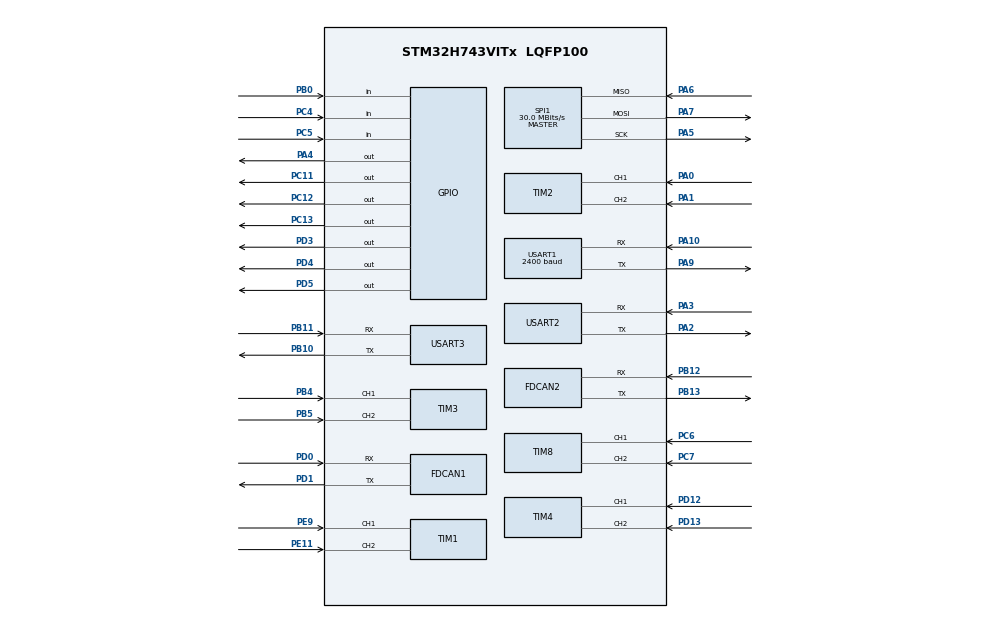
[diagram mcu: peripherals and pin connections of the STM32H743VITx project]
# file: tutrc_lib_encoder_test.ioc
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Dma.Request0=USART1_RX
Dma.Request1=USART2_RX
Dma.Request2=USART3_RX
Dma.USART1_RX.0.Direction=DMA_PERIPH_TO_MEMORY
Dma.USART1_RX.0.EventEnable=DISABLE
Dma.USART1_RX.0.FIFOMode=DMA_FIFOMODE_DISABLE
Dma.USART1_RX.0.Instance=DMA1_Stream0
Dma.USART1_RX.0.MemDataAlignment=DMA_MDATAALIGN_BYTE
Dma.USART1_RX.0.MemInc=DMA_MINC_ENABLE
Dma.USART1_RX.0.Mode=DMA_CIRCULAR
Dma.USART1_RX.0.PeriphDataAlignment=DMA_PDATAALIGN_BYTE
Dma.USART1_RX.0.PeriphInc=DMA_PINC_DISABLE
Dma.USART1_RX.0.Polarity=HAL_DMAMUX_REQ_GEN_RISING
Dma.USART1_RX.0.Priority=DMA_PRIORITY_LOW
Dma.USART1_RX.0.RequestNumber=1
Dma.USART1_RX.0.SignalID=NONE
Dma.USART1_RX.0.SyncEnable=DISABLE
Dma.USART1_RX.0.SyncPolarity=HAL_DMAMUX_SYNC_NO_EVENT
Dma.USART1_RX.0.SyncRequestNumber=1
Dma.USART1_RX.0.SyncSignalID=NONE
Dma.USART2_RX.1.Direction=DMA_PERIPH_TO_MEMORY
Dma.USART2_RX.1.EventEnable=DISABLE
Dma.USART2_RX.1.FIFOMode=DMA_FIFOMODE_DISABLE
Dma.USART2_RX.1.Instance=DMA1_Stream1
Dma.USART2_RX.1.MemDataAlignment=DMA_MDATAALIGN_BYTE
Dma.USART2_RX.1.MemInc=DMA_MINC_ENABLE
Dma.USART2_RX.1.Mode=DMA_CIRCULAR
Dma.USART2_RX.1.PeriphDataAlignment=DMA_PDATAALIGN_BYTE
Dma.USART2_RX.1.PeriphInc=DMA_PINC_DISABLE
Dma.USART2_RX.1.Polarity=HAL_DMAMUX_REQ_GEN_RISING
Dma.USART2_RX.1.Priority=DMA_PRIORITY_LOW
Dma.USART2_RX.1.RequestNumber=1
Dma.USART2_RX.1.SignalID=NONE
Dma.USART2_RX.1.SyncEnable=DISABLE
Dma.USART2_RX.1.SyncPolarity=HAL_DMAMUX_SYNC_NO_EVENT
Dma.USART2_RX.1.SyncRequestNumber=1
Dma.USART2_RX.1.SyncSignalID=NONE
Dma.USART3_RX.2.Direction=DMA_PERIPH_TO_MEMORY
Dma.USART3_RX.2.EventEnable=DISABLE
Dma.USART3_RX.2.FIFOMode=DMA_FIFOMODE_DISABLE
Dma.USART3_RX.2.Instance=DMA1_Stream2
Dma.USART3_RX.2.MemDataAlignment=DMA_MDATAALIGN_BYTE
Dma.USART3_RX.2.MemInc=DMA_MINC_ENABLE
Dma.USART3_RX.2.Mode=DMA_CIRCULAR
Dma.USART3_RX.2.PeriphDataAlignment=DMA_PDATAALIGN_BYTE
Dma.USART3_RX.2.PeriphInc=DMA_PINC_DISABLE
Dma.USART3_RX.2.Polarity=HAL_DMAMUX_REQ_GEN_RISING
Dma.USART3_RX.2.Priority=DMA_PRIORITY_LOW
Dma.USART3_RX.2.RequestNumber=1
Dma.USART3_RX.2.SignalID=NONE
Dma.USART3_RX.2.SyncEnable=DISABLE
Dma.USART3_RX.2.SyncPolarity=HAL_DMAMUX_SYNC_NO_EVENT
Dma.USART3_RX.2.SyncRequestNumber=1
Dma.USART3_RX.2.SyncSignalID=NONE
FDCAN1.NominalPrescaler=5
FDCAN1.NominalTimeSeg1=13
FDCAN1.RxBuffersNbr=64
FDCAN1.RxFifo0ElmtsNbr=64
FDCAN1.StdFiltersNbr=128
FDCAN1.TxFifoQueueElmtsNbr=32
FDCAN2.MessageRAMOffset=2560/2
FDCAN2.NominalPrescaler=5
FDCAN2.NominalTimeSeg1=13
FDCAN2.RxBuffersNbr=64
FDCAN2.RxFifo1ElmtsNbr=64
FDCAN2.StdFiltersNbr=128
FDCAN2.TxFifoQueueElmtsNbr=32
Mcu.Family=STM32H7
Mcu.Name=STM32H743VITx
Mcu.Package=LQFP100
NVIC.DMA1_Stream0_IRQn=true\:0\:0\:false\:false\:true\:false\:true\:true
NVIC.DMA1_Stream1_IRQn=true\:0\:0\:false\:false\:true\:false\:true\:true
NVIC.DMA1_Stream2_IRQn=true\:0\:0\:false\:false\:true\:false\:true\:true
NVIC.FDCAN1_IT0_IRQn=true\:0\:0\:true\:false\:true\:true\:true\:true
NVIC.FDCAN2_IT0_IRQn=true\:0\:0\:false\:false\:true\:true\:true\:true
NVIC.PriorityGroup=NVIC_PRIORITYGROUP_4
NVIC.TIM5_IRQn=true\:1\:0\:true\:false\:true\:true\:true\:true
NVIC.TIM6_DAC_IRQn=true\:0\:0\:false\:false\:true\:true\:true\:true
NVIC.TIM7_IRQn=true\:0\:0\:false\:false\:true\:true\:true\:true
NVIC.TIM8_UP_TIM13_IRQn=true\:1\:0\:true\:false\:true\:true\:true\:true
NVIC.USART3_IRQn=true\:0\:0\:false\:false\:true\:true\:true\:true
PA0.Signal=S_TIM2_CH1
PA1.Signal=S_TIM2_CH2
PA10.Mode=Asynchronous
PA10.Signal=USART1_RX
PA12.Signal=USART1_DE
PA13\ (JTMS/SWDIO).Mode=Serial_Wire
PA13\ (JTMS/SWDIO).Signal=DEBUG_JTMS-SWDIO
PA14\ (JTCK/SWCLK).Mode=Serial_Wire
PA14\ (JTCK/SWCLK).Signal=DEBUG_JTCK-SWCLK
PA2.Mode=Asynchronous
PA2.Signal=USART2_TX
PA3.Mode=Asynchronous
PA3.Signal=USART2_RX
PA4.Signal=GPIO_Output
PA5.Mode=Full_Duplex_Master
PA5.Signal=SPI1_SCK
PA6.Mode=Full_Duplex_Master
PA6.Signal=SPI1_MISO
PA7.Mode=Full_Duplex_Master
PA7.Signal=SPI1_MOSI
PA9.Mode=Asynchronous
PA9.Signal=USART1_TX
PB0.Signal=GPIO_Input
PB10.Mode=Asynchronous
PB10.Signal=USART3_TX
PB11.Mode=Asynchronous
PB11.Signal=USART3_RX
PB12.Mode=FDCAN_Activate
PB12.Signal=FDCAN2_RX
PB13.Mode=FDCAN_Activate
PB13.Signal=FDCAN2_TX
PB14.Signal=USART3_DE
PB3\ (JTDO/TRACESWO).Signal=DEBUG_JTDO-SWO
PB4\ (NJTRST).Signal=S_TIM3_CH1
PB5.Signal=S_TIM3_CH2
PB6.Signal=I2C1_SCL
PB9.Signal=I2C1_SDA
PC11.Signal=GPIO_Output
PC12.Signal=GPIO_Output
PC13.Signal=GPIO_Output
PC4.Signal=GPIO_Input
PC5.Signal=GPIO_Input
PC6.Signal=S_TIM8_CH1
PC7.Signal=S_TIM8_CH2
PD0.Mode=FDCAN_Activate
PD0.Signal=FDCAN1_RX
PD1.Mode=FDCAN_Activate
PD1.Signal=FDCAN1_TX
PD12.Signal=S_TIM4_CH1
PD13.Signal=S_TIM4_CH2
PD3.Signal=GPIO_Output
PD4.Signal=GPIO_Output
PD5.Signal=GPIO_Output
PE11.Signal=S_TIM1_CH2
PE9.Signal=S_TIM1_CH1
PH0-OSC_IN\ (PH0).Mode=HSE-External-Oscillator
PH0-OSC_IN\ (PH0).Signal=RCC_OSC_IN
PH1-OSC_OUT\ (PH1).Mode=HSE-External-Oscillator
PH1-OSC_OUT\ (PH1).Signal=RCC_OSC_OUT
ProjectManager.HeapSize=0x200
ProjectManager.StackSize=0x400
ProjectManager.TargetToolchain=STM32CubeIDE
RCC.ADCFreq_Value=60000000
RCC.APB1Freq_Value=120000000
RCC.APB2Freq_Value=120000000
RCC.APB3Freq_Value=120000000
RCC.APB4Freq_Value=120000000
RCC.CortexFreq_Value=480000000
RCC.D1PPRE=RCC_APB3_DIV2
RCC.D2PPRE1=RCC_APB1_DIV2
RCC.D2PPRE2=RCC_APB2_DIV2
RCC.D3PPRE=RCC_APB4_DIV2
RCC.DIVM1=2
RCC.DIVN1=60
RCC.DIVN2=240
RCC.DIVP2=4
RCC.DIVQ1=12
RCC.HCLKFreq_Value=240000000
RCC.HPRE=RCC_HCLK_DIV2
RCC.HSE_VALUE=32000000
RCC.PLLFRACN=0
RCC.PLLSourceVirtual=RCC_PLLSOURCE_HSE
RCC.PWR_Regulator_Voltage_Scale=PWR_REGULATOR_VOLTAGE_SCALE0
RCC.SPI123CLockSelection=RCC_SPI123CLKSOURCE_PLL2
RCC.SYSCLKFreq_VALUE=480000000
RCC.SYSCLKSource=RCC_SYSCLKSOURCE_PLLCLK
RCC.USBFreq_Value=80000000
SH.S_TIM1_CH1.0=TIM1_CH1,Encoder_Interface
SH.S_TIM1_CH2.0=TIM1_CH2,Encoder_Interface
SH.S_TIM2_CH1.0=TIM2_CH1,Encoder_Interface
SH.S_TIM2_CH2.0=TIM2_CH2,Encoder_Interface
SH.S_TIM3_CH1.0=TIM3_CH1,Encoder_Interface
SH.S_TIM3_CH2.0=TIM3_CH2,Encoder_Interface
SH.S_TIM4_CH1.0=TIM4_CH1,Encoder_Interface
SH.S_TIM4_CH2.0=TIM4_CH2,Encoder_Interface
SH.S_TIM8_CH1.0=TIM8_CH1,Encoder_Interface
SH.S_TIM8_CH2.0=TIM8_CH2,Encoder_Interface
SPI1.BaudRatePrescaler=SPI_BAUDRATEPRESCALER_2
SPI1.CalculateBaudRate=30.0 MBits/s
SPI1.DataSize=SPI_DATASIZE_8BIT
SPI1.Direction=SPI_DIRECTION_2LINES
SPI1.IOSwap=SPI_IO_SWAP_ENABLE
SPI1.MasterKeepIOState=SPI_MASTER_KEEP_IO_STATE_ENABLE
SPI1.MasterReceiverAutoSusp=SPI_MASTER_RX_AUTOSUSP_ENABLE
SPI1.Mode=SPI_MODE_MASTER
SPI1.NSSPMode=SPI_NSS_PULSE_ENABLE
SPI1.VirtualType=VM_MASTER
TIM1.EncoderMode=TIM_ENCODERMODE_TI12
TIM13.Period=10000-1
TIM13.Prescaler=240-1
TIM2.EncoderMode=TIM_ENCODERMODE_TI12
TIM3.EncoderMode=TIM_ENCODERMODE_TI12
TIM4.EncoderMode=TIM_ENCODERMODE_TI12
TIM5.Period=10000-1
TIM5.Prescaler=240-1
TIM6.Prescaler=240-1
TIM7.Period=1000-1
TIM7.Prescaler=240-1
TIM8.EncoderMode=TIM_ENCODERMODE_TI12
USART1.BaudRate=2400
USART1.VirtualMode-Asynchronous=VM_ASYNC
USART2.VirtualMode-Asynchronous=VM_ASYNC
USART3.VirtualMode-Asynchronous=VM_ASYNC
VP_TIM13_VS_ClockSourceINT.Mode=Enable_Timer
VP_TIM5_VS_ClockSourceINT.Mode=Internal
VP_TIM6_VS_ClockSourceINT.Mode=Enable_Timer
VP_TIM7_VS_ClockSourceINT.Mode=Enable_Timer
board=custom

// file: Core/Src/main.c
/* USER CODE BEGIN Header */
/**
  ******************************************************************************
  * @file           : main.c
  * @brief          : Main program body
  ******************************************************************************
  * @attention
  *
  * <h2><center>&copy; Copyright (c) 2024 STMicroelectronics.
  * All rights reserved.</center></h2>
  *
  * This software component is licensed by ST under BSD 3-Clause license,
  * the "License"; You may not use this file except in compliance with the
  * License. You may obtain a copy of the License at:
  *                        opensource.org/licenses/BSD-3-Clause
  *
  ******************************************************************************
  */
/* USER CODE END Header */
#include "main.h"

FDCAN_HandleTypeDef hfdcan1;
FDCAN_HandleTypeDef hfdcan2;

SPI_HandleTypeDef hspi1;

TIM_HandleTypeDef htim1;
TIM_HandleTypeDef htim2;
TIM_HandleTypeDef htim3;
TIM_HandleTypeDef htim4;
TIM_HandleTypeDef htim5;
TIM_HandleTypeDef htim6;
TIM_HandleTypeDef htim7;
TIM_HandleTypeDef htim8;
TIM_HandleTypeDef htim13;

UART_HandleTypeDef huart1;
UART_HandleTypeDef huart2;
UART_HandleTypeDef huart3;
DMA_HandleTypeDef hdma_usart1_rx;
DMA_HandleTypeDef hdma_usart2_rx;
DMA_HandleTypeDef hdma_usart3_rx;

void SystemClock_Config(void);
static void MX_GPIO_Init(void);
static void MX_DMA_Init(void);
static void MX_FDCAN2_Init(void);
static void MX_TIM1_Init(void);
static void MX_TIM2_Init(void);
static void MX_TIM3_Init(void);
static void MX_TIM4_Init(void);
static void MX_TIM8_Init(void);
static void MX_USART2_UART_Init(void);
static void MX_TIM6_Init(void);
static void MX_TIM7_Init(void);
static void MX_SPI1_Init(void);
static void MX_TIM13_Init(void);
static void MX_USART1_UART_Init(void);
static void MX_FDCAN1_Init(void);
static void MX_USART3_UART_Init(void);
static void MX_TIM5_Init(void);
/* USER CODE BEGIN PFP */
void cppmain();
/* USER CODE END PFP */

int main(void)
{

  /* MCU Configuration--------------------------------------------------------*/

  /* Reset of all peripherals, Initializes the Flash interface and the Systick. */
  HAL_Init();

  /* Configure the system clock */
  SystemClock_Config();

  /* Initialize all configured peripherals */
  MX_GPIO_Init();
  MX_DMA_Init();
  MX_FDCAN2_Init();
  MX_TIM1_Init();
  MX_TIM2_Init();
  MX_TIM3_Init();
  MX_TIM4_Init();
  MX_TIM8_Init();
  MX_USART2_UART_Init();
  MX_TIM6_Init();
  MX_TIM7_Init();
  MX_SPI1_Init();
  MX_TIM13_Init();
  MX_USART1_UART_Init();
  MX_FDCAN1_Init();
  MX_USART3_UART_Init();
  MX_TIM5_Init();
  /* USER CODE BEGIN 2 */
cppmain();
  /* USER CODE END 2 */

  /* Infinite loop */
  while (1)
  {

  }
}

void SystemClock_Config(void)
{
  RCC_OscInitTypeDef RCC_OscInitStruct = {0};
  RCC_ClkInitTypeDef RCC_ClkInitStruct = {0};

  /** Supply configuration update enable
  */
  HAL_PWREx_ConfigSupply(PWR_LDO_SUPPLY);
  /** Configure the main internal regulator output voltage
  */
  __HAL_PWR_VOLTAGESCALING_CONFIG(PWR_REGULATOR_VOLTAGE_SCALE0);

  while(!__HAL_PWR_GET_FLAG(PWR_FLAG_VOSRDY)) {}
  /** Macro to configure the PLL clock source
  */
  __HAL_RCC_PLL_PLLSOURCE_CONFIG(RCC_PLLSOURCE_HSE);
  /** Initializes the RCC Oscillators according to the specified parameters
  * in the RCC_OscInitTypeDef structure.
  */
  RCC_OscInitStruct.OscillatorType = RCC_OSCILLATORTYPE_HSE;
  RCC_OscInitStruct.HSEState = RCC_HSE_ON;
  RCC_OscInitStruct.PLL.PLLState = RCC_PLL_ON;
  RCC_OscInitStruct.PLL.PLLSource = RCC_PLLSOURCE_HSE;
  RCC_OscInitStruct.PLL.PLLM = 2;
  RCC_OscInitStruct.PLL.PLLN = 60;
  RCC_OscInitStruct.PLL.PLLP = 2;
  RCC_OscInitStruct.PLL.PLLQ = 12;
  RCC_OscInitStruct.PLL.PLLR = 2;
  RCC_OscInitStruct.PLL.PLLRGE = RCC_PLL1VCIRANGE_3;
  RCC_OscInitStruct.PLL.PLLVCOSEL = RCC_PLL1VCOWIDE;
  RCC_OscInitStruct.PLL.PLLFRACN = 0;
  if (HAL_RCC_OscConfig(&RCC_OscInitStruct) != HAL_OK)
  {
    Error_Handler();
  }
  /** Initializes the CPU, AHB and APB buses clocks
  */
  RCC_ClkInitStruct.ClockType = RCC_CLOCKTYPE_HCLK|RCC_CLOCKTYPE_SYSCLK
                              |RCC_CLOCKTYPE_PCLK1|RCC_CLOCKTYPE_PCLK2
                              |RCC_CLOCKTYPE_D3PCLK1|RCC_CLOCKTYPE_D1PCLK1;
  RCC_ClkInitStruct.SYSCLKSource = RCC_SYSCLKSOURCE_PLLCLK;
  RCC_ClkInitStruct.SYSCLKDivider = RCC_SYSCLK_DIV1;
  RCC_ClkInitStruct.AHBCLKDivider = RCC_HCLK_DIV2;
  RCC_ClkInitStruct.APB3CLKDivider = RCC_APB3_DIV2;
  RCC_ClkInitStruct.APB1CLKDivider = RCC_APB1_DIV2;
  RCC_ClkInitStruct.APB2CLKDivider = RCC_APB2_DIV2;
  RCC_ClkInitStruct.APB4CLKDivider = RCC_APB4_DIV2;

  if (HAL_RCC_ClockConfig(&RCC_ClkInitStruct, FLASH_LATENCY_4) != HAL_OK)
  {
    Error_Handler();
  }
}

static void MX_FDCAN1_Init(void)
{

  hfdcan1.Instance = FDCAN1;
  hfdcan1.Init.FrameFormat = FDCAN_FRAME_CLASSIC;
  hfdcan1.Init.Mode = FDCAN_MODE_NORMAL;
  hfdcan1.Init.AutoRetransmission = DISABLE;
  hfdcan1.Init.TransmitPause = DISABLE;
  hfdcan1.Init.ProtocolException = DISABLE;
  hfdcan1.Init.NominalPrescaler = 5;
  hfdcan1.Init.NominalSyncJumpWidth = 1;
  hfdcan1.Init.NominalTimeSeg1 = 13;
  hfdcan1.Init.NominalTimeSeg2 = 2;
  hfdcan1.Init.DataPrescaler = 1;
  hfdcan1.Init.DataSyncJumpWidth = 1;
  hfdcan1.Init.DataTimeSeg1 = 1;
  hfdcan1.Init.DataTimeSeg2 = 1;
  hfdcan1.Init.MessageRAMOffset = 0;
  hfdcan1.Init.StdFiltersNbr = 128;
  hfdcan1.Init.ExtFiltersNbr = 0;
  hfdcan1.Init.RxFifo0ElmtsNbr = 64;
  hfdcan1.Init.RxFifo0ElmtSize = FDCAN_DATA_BYTES_8;
  hfdcan1.Init.RxFifo1ElmtsNbr = 0;
  hfdcan1.Init.RxFifo1ElmtSize = FDCAN_DATA_BYTES_8;
  hfdcan1.Init.RxBuffersNbr = 64;
  hfdcan1.Init.RxBufferSize = FDCAN_DATA_BYTES_8;
  hfdcan1.Init.TxEventsNbr = 0;
  hfdcan1.Init.TxBuffersNbr = 0;
  hfdcan1.Init.TxFifoQueueElmtsNbr = 32;
  hfdcan1.Init.TxFifoQueueMode = FDCAN_TX_FIFO_OPERATION;
  hfdcan1.Init.TxElmtSize = FDCAN_DATA_BYTES_8;
  if (HAL_FDCAN_Init(&hfdcan1) != HAL_OK)
  {
    Error_Handler();
  }

}

static void MX_FDCAN2_Init(void)
{

  hfdcan2.Instance = FDCAN2;
  hfdcan2.Init.FrameFormat = FDCAN_FRAME_CLASSIC;
  hfdcan2.Init.Mode = FDCAN_MODE_NORMAL;
  hfdcan2.Init.AutoRetransmission = DISABLE;
  hfdcan2.Init.TransmitPause = DISABLE;
  hfdcan2.Init.ProtocolException = DISABLE;
  hfdcan2.Init.NominalPrescaler = 5;
  hfdcan2.Init.NominalSyncJumpWidth = 1;
  hfdcan2.Init.NominalTimeSeg1 = 13;
  hfdcan2.Init.NominalTimeSeg2 = 2;
  hfdcan2.Init.DataPrescaler = 1;
  hfdcan2.Init.DataSyncJumpWidth = 1;
  hfdcan2.Init.DataTimeSeg1 = 1;
  hfdcan2.Init.DataTimeSeg2 = 1;
  hfdcan2.Init.MessageRAMOffset = 2560/2;
  hfdcan2.Init.StdFiltersNbr = 128;
  hfdcan2.Init.ExtFiltersNbr = 0;
  hfdcan2.Init.RxFifo0ElmtsNbr = 0;
  hfdcan2.Init.RxFifo0ElmtSize = FDCAN_DATA_BYTES_8;
  hfdcan2.Init.RxFifo1ElmtsNbr = 64;
  hfdcan2.Init.RxFifo1ElmtSize = FDCAN_DATA_BYTES_8;
  hfdcan2.Init.RxBuffersNbr = 64;
  hfdcan2.Init.RxBufferSize = FDCAN_DATA_BYTES_8;
  hfdcan2.Init.TxEventsNbr = 0;
  hfdcan2.Init.TxBuffersNbr = 0;
  hfdcan2.Init.TxFifoQueueElmtsNbr = 32;
  hfdcan2.Init.TxFifoQueueMode = FDCAN_TX_FIFO_OPERATION;
  hfdcan2.Init.TxElmtSize = FDCAN_DATA_BYTES_8;
  if (HAL_FDCAN_Init(&hfdcan2) != HAL_OK)
  {
    Error_Handler();
  }

}

static void MX_SPI1_Init(void)
{

  /* SPI1 parameter configuration*/
  hspi1.Instance = SPI1;
  hspi1.Init.Mode = SPI_MODE_MASTER;
  hspi1.Init.Direction = SPI_DIRECTION_2LINES;
  hspi1.Init.DataSize = SPI_DATASIZE_8BIT;
  hspi1.Init.CLKPolarity = SPI_POLARITY_LOW;
  hspi1.Init.CLKPhase = SPI_PHASE_1EDGE;
  hspi1.Init.NSS = SPI_NSS_SOFT;
  hspi1.Init.BaudRatePrescaler = SPI_BAUDRATEPRESCALER_2;
  hspi1.Init.FirstBit = SPI_FIRSTBIT_MSB;
  hspi1.Init.TIMode = SPI_TIMODE_DISABLE;
  hspi1.Init.CRCCalculation = SPI_CRCCALCULATION_DISABLE;
  hspi1.Init.CRCPolynomial = 0x0;
  hspi1.Init.NSSPMode = SPI_NSS_PULSE_ENABLE;
  hspi1.Init.NSSPolarity = SPI_NSS_POLARITY_LOW;
  hspi1.Init.FifoThreshold = SPI_FIFO_THRESHOLD_01DATA;
  hspi1.Init.TxCRCInitializationPattern = SPI_CRC_INITIALIZATION_ALL_ZERO_PATTERN;
  hspi1.Init.RxCRCInitializationPattern = SPI_CRC_INITIALIZATION_ALL_ZERO_PATTERN;
  hspi1.Init.MasterSSIdleness = SPI_MASTER_SS_IDLENESS_00CYCLE;
  hspi1.Init.MasterInterDataIdleness = SPI_MASTER_INTERDATA_IDLENESS_00CYCLE;
  hspi1.Init.MasterReceiverAutoSusp = SPI_MASTER_RX_AUTOSUSP_ENABLE;
  hspi1.Init.MasterKeepIOState = SPI_MASTER_KEEP_IO_STATE_ENABLE;
  hspi1.Init.IOSwap = SPI_IO_SWAP_ENABLE;
  if (HAL_SPI_Init(&hspi1) != HAL_OK)
  {
    Error_Handler();
  }

}

static void MX_TIM1_Init(void)
{

  TIM_Encoder_InitTypeDef sConfig = {0};
  TIM_MasterConfigTypeDef sMasterConfig = {0};

  htim1.Instance = TIM1;
  htim1.Init.Prescaler = 0;
  htim1.Init.CounterMode = TIM_COUNTERMODE_UP;
  htim1.Init.Period = 65535;
  htim1.Init.ClockDivision = TIM_CLOCKDIVISION_DIV1;
  htim1.Init.RepetitionCounter = 0;
  htim1.Init.AutoReloadPreload = TIM_AUTORELOAD_PRELOAD_DISABLE;
  sConfig.EncoderMode = TIM_ENCODERMODE_TI12;
  sConfig.IC1Polarity = TIM_ICPOLARITY_RISING;
  sConfig.IC1Selection = TIM_ICSELECTION_DIRECTTI;
  sConfig.IC1Prescaler = TIM_ICPSC_DIV1;
  sConfig.IC1Filter = 0;
  sConfig.IC2Polarity = TIM_ICPOLARITY_RISING;
  sConfig.IC2Selection = TIM_ICSELECTION_DIRECTTI;
  sConfig.IC2Prescaler = TIM_ICPSC_DIV1;
  sConfig.IC2Filter = 0;
  if (HAL_TIM_Encoder_Init(&htim1, &sConfig) != HAL_OK)
  {
    Error_Handler();
  }
  sMasterConfig.MasterOutputTrigger = TIM_TRGO_RESET;
  sMasterConfig.MasterOutputTrigger2 = TIM_TRGO2_RESET;
  sMasterConfig.MasterSlaveMode = TIM_MASTERSLAVEMODE_DISABLE;
  if (HAL_TIMEx_MasterConfigSynchronization(&htim1, &sMasterConfig) != HAL_OK)
  {
    Error_Handler();
  }

}

static void MX_TIM2_Init(void)
{

  TIM_Encoder_InitTypeDef sConfig = {0};
  TIM_MasterConfigTypeDef sMasterConfig = {0};

  htim2.Instance = TIM2;
  htim2.Init.Prescaler = 0;
  htim2.Init.CounterMode = TIM_COUNTERMODE_UP;
  htim2.Init.Period = 4294967295;
  htim2.Init.ClockDivision = TIM_CLOCKDIVISION_DIV1;
  htim2.Init.AutoReloadPreload = TIM_AUTORELOAD_PRELOAD_DISABLE;
  sConfig.EncoderMode = TIM_ENCODERMODE_TI12;
  sConfig.IC1Polarity = TIM_ICPOLARITY_RISING;
  sConfig.IC1Selection = TIM_ICSELECTION_DIRECTTI;
  sConfig.IC1Prescaler = TIM_ICPSC_DIV1;
  sConfig.IC1Filter = 0;
  sConfig.IC2Polarity = TIM_ICPOLARITY_RISING;
  sConfig.IC2Selection = TIM_ICSELECTION_DIRECTTI;
  sConfig.IC2Prescaler = TIM_ICPSC_DIV1;
  sConfig.IC2Filter = 0;
  if (HAL_TIM_Encoder_Init(&htim2, &sConfig) != HAL_OK)
  {
    Error_Handler();
  }
  sMasterConfig.MasterOutputTrigger = TIM_TRGO_RESET;
  sMasterConfig.MasterSlaveMode = TIM_MASTERSLAVEMODE_DISABLE;
  if (HAL_TIMEx_MasterConfigSynchronization(&htim2, &sMasterConfig) != HAL_OK)
  {
    Error_Handler();
  }

}

static void MX_TIM3_Init(void)
{

  TIM_Encoder_InitTypeDef sConfig = {0};
  TIM_MasterConfigTypeDef sMasterConfig = {0};

  htim3.Instance = TIM3;
  htim3.Init.Prescaler = 0;
  htim3.Init.CounterMode = TIM_COUNTERMODE_UP;
  htim3.Init.Period = 65535;
  htim3.Init.ClockDivision = TIM_CLOCKDIVISION_DIV1;
  htim3.Init.AutoReloadPreload = TIM_AUTORELOAD_PRELOAD_DISABLE;
  sConfig.EncoderMode = TIM_ENCODERMODE_TI12;
  sConfig.IC1Polarity = TIM_ICPOLARITY_RISING;
  sConfig.IC1Selection = TIM_ICSELECTION_DIRECTTI;
  sConfig.IC1Prescaler = TIM_ICPSC_DIV1;
  sConfig.IC1Filter = 0;
  sConfig.IC2Polarity = TIM_ICPOLARITY_RISING;
  sConfig.IC2Selection = TIM_ICSELECTION_DIRECTTI;
  sConfig.IC2Prescaler = TIM_ICPSC_DIV1;
  sConfig.IC2Filter = 0;
  if (HAL_TIM_Encoder_Init(&htim3, &sConfig) != HAL_OK)
  {
    Error_Handler();
  }
  sMasterConfig.MasterOutputTrigger = TIM_TRGO_RESET;
  sMasterConfig.MasterSlaveMode = TIM_MASTERSLAVEMODE_DISABLE;
  if (HAL_TIMEx_MasterConfigSynchronization(&htim3, &sMasterConfig) != HAL_OK)
  {
    Error_Handler();
  }

}

static void MX_TIM4_Init(void)
{

  TIM_Encoder_InitTypeDef sConfig = {0};
  TIM_MasterConfigTypeDef sMasterConfig = {0};

  htim4.Instance = TIM4;
  htim4.Init.Prescaler = 0;
  htim4.Init.CounterMode = TIM_COUNTERMODE_UP;
  htim4.Init.Period = 65535;
  htim4.Init.ClockDivision = TIM_CLOCKDIVISION_DIV1;
  htim4.Init.AutoReloadPreload = TIM_AUTORELOAD_PRELOAD_DISABLE;
  sConfig.EncoderMode = TIM_ENCODERMODE_TI12;
  sConfig.IC1Polarity = TIM_ICPOLARITY_RISING;
  sConfig.IC1Selection = TIM_ICSELECTION_DIRECTTI;
  sConfig.IC1Prescaler = TIM_ICPSC_DIV1;
  sConfig.IC1Filter = 0;
  sConfig.IC2Polarity = TIM_ICPOLARITY_RISING;
  sConfig.IC2Selection = TIM_ICSELECTION_DIRECTTI;
  sConfig.IC2Prescaler = TIM_ICPSC_DIV1;
  sConfig.IC2Filter = 0;
  if (HAL_TIM_Encoder_Init(&htim4, &sConfig) != HAL_OK)
  {
    Error_Handler();
  }
  sMasterConfig.MasterOutputTrigger = TIM_TRGO_RESET;
  sMasterConfig.MasterSlaveMode = TIM_MASTERSLAVEMODE_DISABLE;
  if (HAL_TIMEx_MasterConfigSynchronization(&htim4, &sMasterConfig) != HAL_OK)
  {
    Error_Handler();
  }

}

static void MX_TIM5_Init(void)
{

  TIM_ClockConfigTypeDef sClockSourceConfig = {0};
  TIM_MasterConfigTypeDef sMasterConfig = {0};

  htim5.Instance = TIM5;
  htim5.Init.Prescaler = 240-1;
  htim5.Init.CounterMode = TIM_COUNTERMODE_UP;
  htim5.Init.Period = 10000-1;
  htim5.Init.ClockDivision = TIM_CLOCKDIVISION_DIV1;
  htim5.Init.AutoReloadPreload = TIM_AUTORELOAD_PRELOAD_DISABLE;
  if (HAL_TIM_Base_Init(&htim5) != HAL_OK)
  {
    Error_Handler();
  }
  sClockSourceConfig.ClockSource = TIM_CLOCKSOURCE_INTERNAL;
  if (HAL_TIM_ConfigClockSource(&htim5, &sClockSourceConfig) != HAL_OK)
  {
    Error_Handler();
  }
  sMasterConfig.MasterOutputTrigger = TIM_TRGO_RESET;
  sMasterConfig.MasterSlaveMode = TIM_MASTERSLAVEMODE_DISABLE;
  if (HAL_TIMEx_MasterConfigSynchronization(&htim5, &sMasterConfig) != HAL_OK)
  {
    Error_Handler();
  }

}

static void MX_TIM6_Init(void)
{

  TIM_MasterConfigTypeDef sMasterConfig = {0};

  htim6.Instance = TIM6;
  htim6.Init.Prescaler = 240-1;
  htim6.Init.CounterMode = TIM_COUNTERMODE_UP;
  htim6.Init.Period = 65535;
  htim6.Init.AutoReloadPreload = TIM_AUTORELOAD_PRELOAD_DISABLE;
  if (HAL_TIM_Base_Init(&htim6) != HAL_OK)
  {
    Error_Handler();
  }
  sMasterConfig.MasterOutputTrigger = TIM_TRGO_RESET;
  sMasterConfig.MasterSlaveMode = TIM_MASTERSLAVEMODE_DISABLE;
  if (HAL_TIMEx_MasterConfigSynchronization(&htim6, &sMasterConfig) != HAL_OK)
  {
    Error_Handler();
  }

}

static void MX_TIM7_Init(void)
{

  TIM_MasterConfigTypeDef sMasterConfig = {0};

  htim7.Instance = TIM7;
  htim7.Init.Prescaler = 240-1;
  htim7.Init.CounterMode = TIM_COUNTERMODE_UP;
  htim7.Init.Period = 1000-1;
  htim7.Init.AutoReloadPreload = TIM_AUTORELOAD_PRELOAD_DISABLE;
  if (HAL_TIM_Base_Init(&htim7) != HAL_OK)
  {
    Error_Handler();
  }
  sMasterConfig.MasterOutputTrigger = TIM_TRGO_RESET;
  sMasterConfig.MasterSlaveMode = TIM_MASTERSLAVEMODE_DISABLE;
  if (HAL_TIMEx_MasterConfigSynchronization(&htim7, &sMasterConfig) != HAL_OK)
  {
    Error_Handler();
  }

}

static void MX_TIM8_Init(void)
{

  TIM_Encoder_InitTypeDef sConfig = {0};
  TIM_MasterConfigTypeDef sMasterConfig = {0};

  htim8.Instance = TIM8;
  htim8.Init.Prescaler = 0;
  htim8.Init.CounterMode = TIM_COUNTERMODE_UP;
  htim8.Init.Period = 65535;
  htim8.Init.ClockDivision = TIM_CLOCKDIVISION_DIV1;
  htim8.Init.RepetitionCounter = 0;
  htim8.Init.AutoReloadPreload = TIM_AUTORELOAD_PRELOAD_DISABLE;
  sConfig.EncoderMode = TIM_ENCODERMODE_TI12;
  sConfig.IC1Polarity = TIM_ICPOLARITY_RISING;
  sConfig.IC1Selection = TIM_ICSELECTION_DIRECTTI;
  sConfig.IC1Prescaler = TIM_ICPSC_DIV1;
  sConfig.IC1Filter = 0;
  sConfig.IC2Polarity = TIM_ICPOLARITY_RISING;
  sConfig.IC2Selection = TIM_ICSELECTION_DIRECTTI;
  sConfig.IC2Prescaler = TIM_ICPSC_DIV1;
  sConfig.IC2Filter = 0;
  if (HAL_TIM_Encoder_Init(&htim8, &sConfig) != HAL_OK)
  {
    Error_Handler();
  }
  sMasterConfig.MasterOutputTrigger = TIM_TRGO_RESET;
  sMasterConfig.MasterOutputTrigger2 = TIM_TRGO2_RESET;
  sMasterConfig.MasterSlaveMode = TIM_MASTERSLAVEMODE_DISABLE;
  if (HAL_TIMEx_MasterConfigSynchronization(&htim8, &sMasterConfig) != HAL_OK)
  {
    Error_Handler();
  }

}

static void MX_TIM13_Init(void)
{

  htim13.Instance = TIM13;
  htim13.Init.Prescaler = 240-1;
  htim13.Init.CounterMode = TIM_COUNTERMODE_UP;
  htim13.Init.Period = 10000-1;
  htim13.Init.ClockDivision = TIM_CLOCKDIVISION_DIV1;
  htim13.Init.AutoReloadPreload = TIM_AUTORELOAD_PRELOAD_DISABLE;
  if (HAL_TIM_Base_Init(&htim13) != HAL_OK)
  {
    Error_Handler();
  }

}

static void MX_USART1_UART_Init(void)
{

  huart1.Instance = USART1;
  huart1.Init.BaudRate = 2400;
  huart1.Init.WordLength = UART_WORDLENGTH_8B;
  huart1.Init.StopBits = UART_STOPBITS_1;
  huart1.Init.Parity = UART_PARITY_NONE;
  huart1.Init.Mode = UART_MODE_TX_RX;
  huart1.Init.HwFlowCtl = UART_HWCONTROL_NONE;
  huart1.Init.OverSampling = UART_OVERSAMPLING_16;
  huart1.Init.OneBitSampling = UART_ONE_BIT_SAMPLE_DISABLE;
  huart1.Init.ClockPrescaler = UART_PRESCALER_DIV1;
  huart1.AdvancedInit.AdvFeatureInit = UART_ADVFEATURE_NO_INIT;
  if (HAL_UART_Init(&huart1) != HAL_OK)
  {
    Error_Handler();
  }
  if (HAL_UARTEx_SetTxFifoThreshold(&huart1, UART_TXFIFO_THRESHOLD_1_8) != HAL_OK)
  {
    Error_Handler();
  }
  if (HAL_UARTEx_SetRxFifoThreshold(&huart1, UART_RXFIFO_THRESHOLD_1_8) != HAL_OK)
  {
    Error_Handler();
  }
  if (HAL_UARTEx_DisableFifoMode(&huart1) != HAL_OK)
  {
    Error_Handler();
  }

}

static void MX_USART2_UART_Init(void)
{

  huart2.Instance = USART2;
  huart2.Init.BaudRate = 115200;
  huart2.Init.WordLength = UART_WORDLENGTH_8B;
  huart2.Init.StopBits = UART_STOPBITS_1;
  huart2.Init.Parity = UART_PARITY_NONE;
  huart2.Init.Mode = UART_MODE_TX_RX;
  huart2.Init.HwFlowCtl = UART_HWCONTROL_NONE;
  huart2.Init.OverSampling = UART_OVERSAMPLING_16;
  huart2.Init.OneBitSampling = UART_ONE_BIT_SAMPLE_DISABLE;
  huart2.Init.ClockPrescaler = UART_PRESCALER_DIV1;
  huart2.AdvancedInit.AdvFeatureInit = UART_ADVFEATURE_NO_INIT;
  if (HAL_UART_Init(&huart2) != HAL_OK)
  {
    Error_Handler();
  }
  if (HAL_UARTEx_SetTxFifoThreshold(&huart2, UART_TXFIFO_THRESHOLD_1_8) != HAL_OK)
  {
    Error_Handler();
  }
  if (HAL_UARTEx_SetRxFifoThreshold(&huart2, UART_RXFIFO_THRESHOLD_1_8) != HAL_OK)
  {
    Error_Handler();
  }
  if (HAL_UARTEx_DisableFifoMode(&huart2) != HAL_OK)
  {
    Error_Handler();
  }

}

static void MX_USART3_UART_Init(void)
{

  huart3.Instance = USART3;
  huart3.Init.BaudRate = 115200;
  huart3.Init.WordLength = UART_WORDLENGTH_8B;
  huart3.Init.StopBits = UART_STOPBITS_1;
  huart3.Init.Parity = UART_PARITY_NONE;
  huart3.Init.Mode = UART_MODE_TX_RX;
  huart3.Init.HwFlowCtl = UART_HWCONTROL_NONE;
  huart3.Init.OverSampling = UART_OVERSAMPLING_16;
  huart3.Init.OneBitSampling = UART_ONE_BIT_SAMPLE_DISABLE;
  huart3.Init.ClockPrescaler = UART_PRESCALER_DIV1;
  huart3.AdvancedInit.AdvFeatureInit = UART_ADVFEATURE_NO_INIT;
  if (HAL_UART_Init(&huart3) != HAL_OK)
  {
    Error_Handler();
  }
  if (HAL_UARTEx_SetTxFifoThreshold(&huart3, UART_TXFIFO_THRESHOLD_1_8) != HAL_OK)
  {
    Error_Handler();
  }
  if (HAL_UARTEx_SetRxFifoThreshold(&huart3, UART_RXFIFO_THRESHOLD_1_8) != HAL_OK)
  {
    Error_Handler();
  }
  if (HAL_UARTEx_DisableFifoMode(&huart3) != HAL_OK)
  {
    Error_Handler();
  }

}

static void MX_DMA_Init(void)
{

  /* DMA controller clock enable */
  __HAL_RCC_DMA1_CLK_ENABLE();

  /* DMA interrupt init */
  /* DMA1_Stream0_IRQn interrupt configuration */
  HAL_NVIC_SetPriority(DMA1_Stream0_IRQn, 0, 0);
  HAL_NVIC_EnableIRQ(DMA1_Stream0_IRQn);
  /* DMA1_Stream1_IRQn interrupt configuration */
  HAL_NVIC_SetPriority(DMA1_Stream1_IRQn, 0, 0);
  HAL_NVIC_EnableIRQ(DMA1_Stream1_IRQn);
  /* DMA1_Stream2_IRQn interrupt configuration */
  HAL_NVIC_SetPriority(DMA1_Stream2_IRQn, 0, 0);
  HAL_NVIC_EnableIRQ(DMA1_Stream2_IRQn);

}

static void MX_GPIO_Init(void)
{
  GPIO_InitTypeDef GPIO_InitStruct = {0};

  /* GPIO Ports Clock Enable */
  __HAL_RCC_GPIOC_CLK_ENABLE();
  __HAL_RCC_GPIOH_CLK_ENABLE();
  __HAL_RCC_GPIOA_CLK_ENABLE();
  __HAL_RCC_GPIOB_CLK_ENABLE();
  __HAL_RCC_GPIOE_CLK_ENABLE();
  __HAL_RCC_GPIOD_CLK_ENABLE();

  /*Configure GPIO pin Output Level */
  HAL_GPIO_WritePin(GPIOC, GPIO_PIN_13|GPIO_PIN_11|GPIO_PIN_12, GPIO_PIN_RESET);

  /*Configure GPIO pin Output Level */
  HAL_GPIO_WritePin(GPIOA, GPIO_PIN_4, GPIO_PIN_RESET);

  /*Configure GPIO pin Output Level */
  HAL_GPIO_WritePin(GPIOD, GPIO_PIN_3|GPIO_PIN_4|GPIO_PIN_5, GPIO_PIN_RESET);

  /*Configure GPIO pins : PC13 PC11 PC12 */
  GPIO_InitStruct.Pin = GPIO_PIN_13|GPIO_PIN_11|GPIO_PIN_12;
  GPIO_InitStruct.Mode = GPIO_MODE_OUTPUT_PP;
  GPIO_InitStruct.Pull = GPIO_NOPULL;
  GPIO_InitStruct.Speed = GPIO_SPEED_FREQ_LOW;
  HAL_GPIO_Init(GPIOC, &GPIO_InitStruct);

  /*Configure GPIO pin : PA4 */
  GPIO_InitStruct.Pin = GPIO_PIN_4;
  GPIO_InitStruct.Mode = GPIO_MODE_OUTPUT_PP;
  GPIO_InitStruct.Pull = GPIO_NOPULL;
  GPIO_InitStruct.Speed = GPIO_SPEED_FREQ_LOW;
  HAL_GPIO_Init(GPIOA, &GPIO_InitStruct);

  /*Configure GPIO pins : PC4 PC5 */
  GPIO_InitStruct.Pin = GPIO_PIN_4|GPIO_PIN_5;
  GPIO_InitStruct.Mode = GPIO_MODE_INPUT;
  GPIO_InitStruct.Pull = GPIO_NOPULL;
  HAL_GPIO_Init(GPIOC, &GPIO_InitStruct);

  /*Configure GPIO pin : PB0 */
  GPIO_InitStruct.Pin = GPIO_PIN_0;
  GPIO_InitStruct.Mode = GPIO_MODE_INPUT;
  GPIO_InitStruct.Pull = GPIO_NOPULL;
  HAL_GPIO_Init(GPIOB, &GPIO_InitStruct);

  /*Configure GPIO pins : PD3 PD4 PD5 */
  GPIO_InitStruct.Pin = GPIO_PIN_3|GPIO_PIN_4|GPIO_PIN_5;
  GPIO_InitStruct.Mode = GPIO_MODE_OUTPUT_PP;
  GPIO_InitStruct.Pull = GPIO_NOPULL;
  GPIO_InitStruct.Speed = GPIO_SPEED_FREQ_LOW;
  HAL_GPIO_Init(GPIOD, &GPIO_InitStruct);

  /*Configure GPIO pins : PB6 PB9 */
  GPIO_InitStruct.Pin = GPIO_PIN_6|GPIO_PIN_9;
  GPIO_InitStruct.Mode = GPIO_MODE_AF_OD;
  GPIO_InitStruct.Pull = GPIO_NOPULL;
  GPIO_InitStruct.Speed = GPIO_SPEED_FREQ_LOW;
  GPIO_InitStruct.Alternate = GPIO_AF4_I2C1;
  HAL_GPIO_Init(GPIOB, &GPIO_InitStruct);

}

void Error_Handler(void)
{
  __disable_irq();
  while (1)
  {
  }
}

/************************ (C) COPYRIGHT STMicroelectronics *****END OF FILE****/
